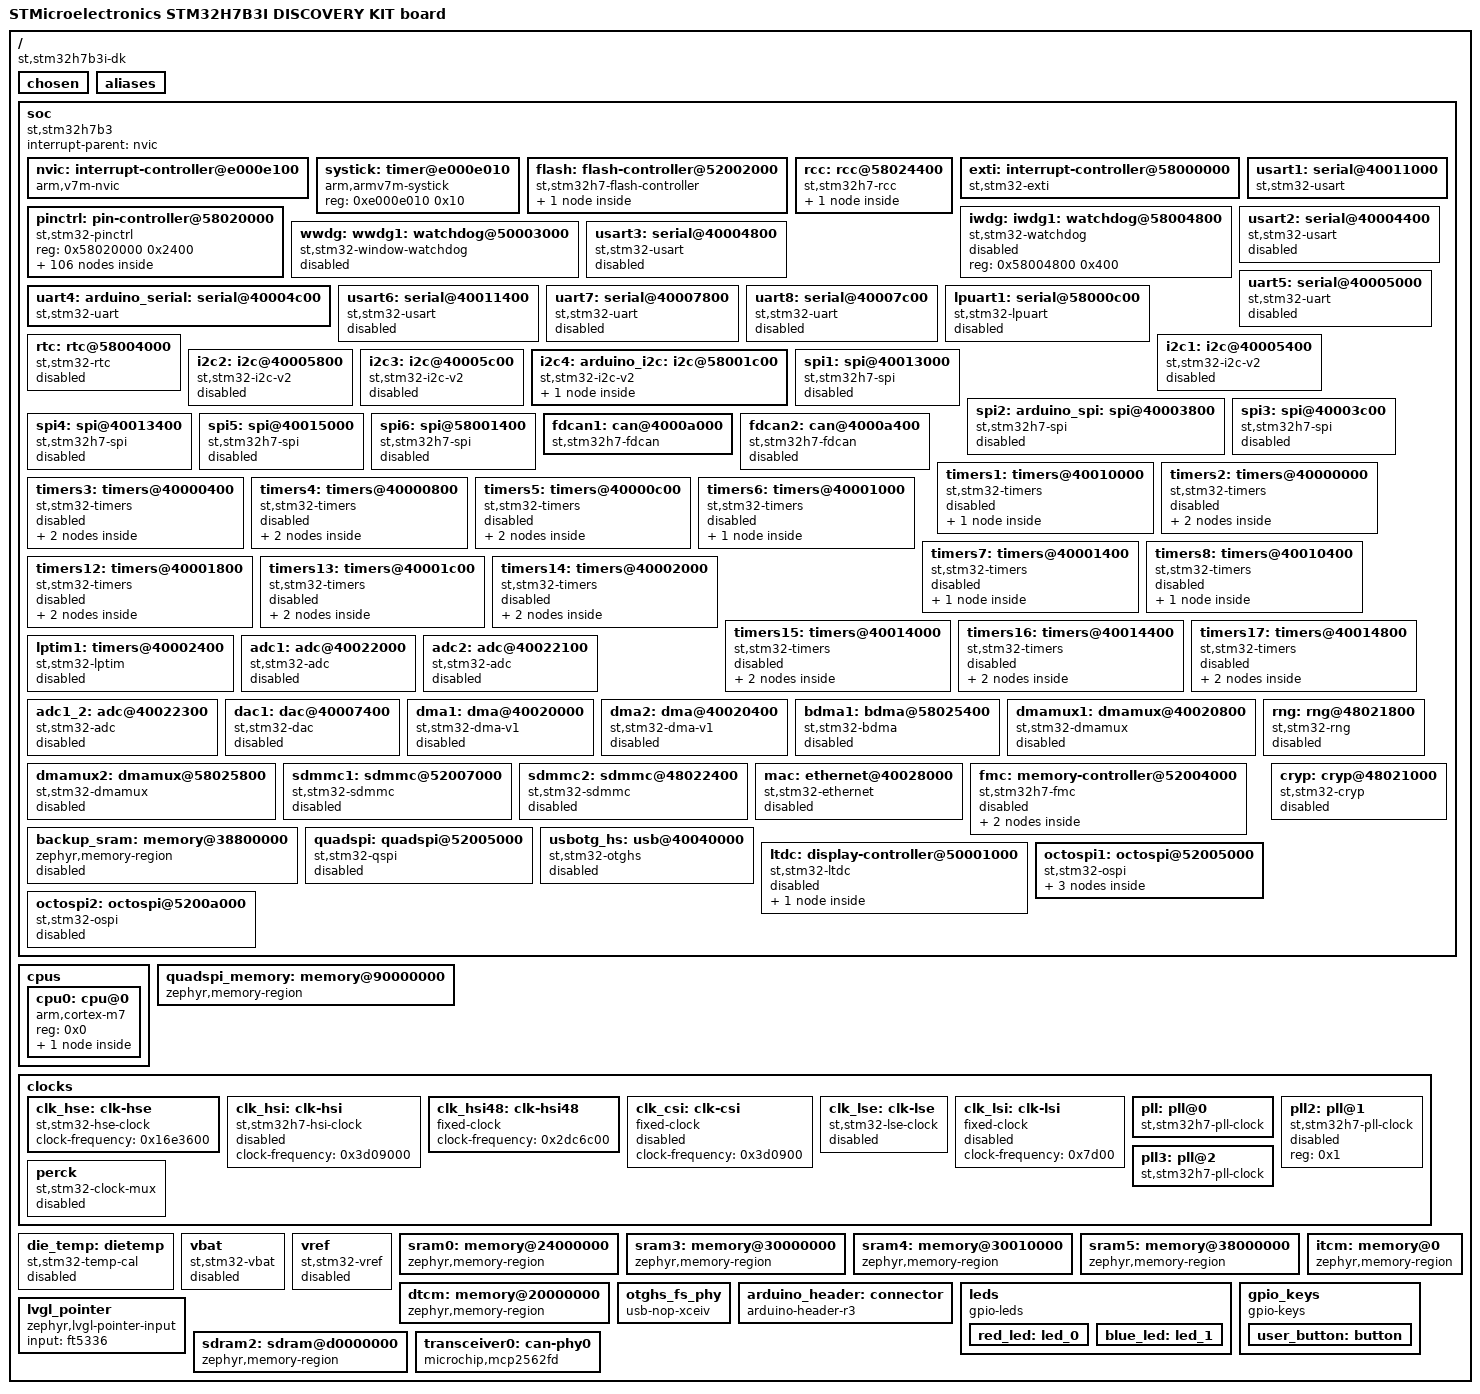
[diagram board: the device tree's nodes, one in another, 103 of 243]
/dts-v1/;

/ {
	#address-cells = < 0x1 >;
	#size-cells = < 0x1 >;
	model = "STMicroelectronics STM32H7B3I DISCOVERY KIT board";
	compatible = "st,stm32h7b3i-dk";
	chosen {
		zephyr,entropy = &rng;
		zephyr,flash-controller = &flash;
		zephyr,console = &usart1;
		zephyr,shell-uart = &usart1;
		zephyr,sram = &sram0;
		zephyr,flash = &flash0;
		zephyr,display = &ltdc;
		zephyr,canbus = &fdcan1;
	};
	aliases {
		led0 = &blue_led;
		led1 = &red_led;
		sw0 = &user_button;
		spi-flash0 = &mx25lm51245;
	};
	soc {
		#address-cells = < 0x1 >;
		#size-cells = < 0x1 >;
		compatible = "st,stm32h7b3", "st,stm32h7", "simple-bus";
		interrupt-parent = < &nvic >;
		ranges;
		nvic: interrupt-controller@e000e100 {
			#address-cells = < 0x1 >;
			compatible = "arm,v7m-nvic";
			reg = < 0xe000e100 0xc00 >;
			interrupt-controller;
			#interrupt-cells = < 0x2 >;
			arm,num-irq-priority-bits = < 0x4 >;
			phandle = < 0x1 >;
		};
		systick: timer@e000e010 {
			compatible = "arm,armv7m-systick";
			reg = < 0xe000e010 0x10 >;
		};
		flash: flash-controller@52002000 {
			compatible = "st,stm32h7-flash-controller";
			reg = < 0x52002000 0x400 >;
			interrupts = < 0x4 0x0 >;
			clocks = < &rcc 0xd4 0x100 >;
			#address-cells = < 0x1 >;
			#size-cells = < 0x1 >;
			flash0: flash@8000000 {
				compatible = "st,stm32-nv-flash", "soc-nv-flash";
				write-block-size = < 0x10 >;
				erase-block-size = < 0x2000 >;
				max-erase-time = < 0x3 >;
				reg = < 0x8000000 0x200000 >;
			};
		};
		rcc: rcc@58024400 {
			compatible = "st,stm32h7-rcc";
			#clock-cells = < 0x2 >;
			reg = < 0x58024400 0x400 >;
			clocks = < &pll >;
			clock-frequency = < 0x10b07600 >;
			d1cpre = < 0x1 >;
			hpre = < 0x1 >;
			d1ppre = < 0x2 >;
			d2ppre1 = < 0x2 >;
			d2ppre2 = < 0x2 >;
			d3ppre = < 0x2 >;
			phandle = < 0x2 >;
			rctl: reset-controller {
				compatible = "st,stm32-rcc-rctl";
				#reset-cells = < 0x1 >;
				phandle = < 0x4 >;
			};
		};
		exti: interrupt-controller@58000000 {
			compatible = "st,stm32-exti";
			interrupt-controller;
			#interrupt-cells = < 0x1 >;
			#address-cells = < 0x1 >;
			reg = < 0x58000000 0x400 >;
			num-lines = < 0x10 >;
			interrupts = < 0x6 0x0 >, < 0x7 0x0 >, < 0x8 0x0 >, < 0x9 0x0 >, < 0xa 0x0 >, < 0x17 0x0 >, < 0x28 0x0 >;
			interrupt-names = "line0", "line1", "line2", "line3", "line4", "line5-9", "line10-15";
			line-ranges = < 0x0 0x1 >, < 0x1 0x1 >, < 0x2 0x1 >, < 0x3 0x1 >, < 0x4 0x1 >, < 0x5 0x5 >, < 0xa 0x6 >;
		};
		pinctrl: pin-controller@58020000 {
			compatible = "st,stm32-pinctrl";
			#address-cells = < 0x1 >;
			#size-cells = < 0x1 >;
			reg = < 0x58020000 0x2400 >;
			gpioa: gpio@58020000 {
				compatible = "st,stm32-gpio";
				gpio-controller;
				#gpio-cells = < 0x2 >;
				reg = < 0x58020000 0x400 >;
				clocks = < &rcc 0xe0 0x1 >;
				phandle = < 0x5d >;
			};
			gpiob: gpio@58020400 {
				compatible = "st,stm32-gpio";
				gpio-controller;
				#gpio-cells = < 0x2 >;
				reg = < 0x58020400 0x400 >;
				clocks = < &rcc 0xe0 0x2 >;
				phandle = < 0x6f >;
			};
			gpioc: gpio@58020800 {
				compatible = "st,stm32-gpio";
				gpio-controller;
				#gpio-cells = < 0x2 >;
				reg = < 0x58020800 0x400 >;
				clocks = < &rcc 0xe0 0x4 >;
				phandle = < 0x6c >;
			};
			gpiod: gpio@58020C00 {
				compatible = "st,stm32-gpio";
				gpio-controller;
				#gpio-cells = < 0x2 >;
				reg = < 0x58020c00 0x400 >;
				clocks = < &rcc 0xe0 0x8 >;
				phandle = < 0x70 >;
			};
			gpioe: gpio@58021000 {
				compatible = "st,stm32-gpio";
				gpio-controller;
				#gpio-cells = < 0x2 >;
				reg = < 0x58021000 0x400 >;
				clocks = < &rcc 0xe0 0x10 >;
				phandle = < 0x6d >;
			};
			gpiof: gpio@58021400 {
				compatible = "st,stm32-gpio";
				gpio-controller;
				#gpio-cells = < 0x2 >;
				reg = < 0x58021400 0x400 >;
				clocks = < &rcc 0xe0 0x20 >;
				phandle = < 0x6e >;
			};
			gpiog: gpio@58021800 {
				compatible = "st,stm32-gpio";
				gpio-controller;
				#gpio-cells = < 0x2 >;
				reg = < 0x58021800 0x400 >;
				clocks = < &rcc 0xe0 0x40 >;
				phandle = < 0x71 >;
			};
			gpioh: gpio@58021C00 {
				compatible = "st,stm32-gpio";
				gpio-controller;
				#gpio-cells = < 0x2 >;
				reg = < 0x58021c00 0x400 >;
				clocks = < &rcc 0xe0 0x80 >;
				phandle = < 0xb >;
			};
			gpioi: gpio@58022000 {
				compatible = "st,stm32-gpio";
				gpio-controller;
				#gpio-cells = < 0x2 >;
				reg = < 0x58022000 0x400 >;
				clocks = < &rcc 0xe0 0x100 >;
				phandle = < 0x19 >;
			};
			gpioj: gpio@58022400 {
				compatible = "st,stm32-gpio";
				gpio-controller;
				#gpio-cells = < 0x2 >;
				reg = < 0x58022400 0x400 >;
				clocks = < &rcc 0xe0 0x200 >;
			};
			gpiok: gpio@58022800 {
				compatible = "st,stm32-gpio";
				gpio-controller;
				#gpio-cells = < 0x2 >;
				reg = < 0x58022800 0x400 >;
				clocks = < &rcc 0xe0 0x400 >;
			};
			fdcan1_rx_pa11: fdcan1_rx_pa11 {
				pinmux = < 0x169 >;
				phandle = < 0x10 >;
			};
			fdcan1_tx_pa12: fdcan1_tx_pa12 {
				pinmux = < 0x189 >;
				phandle = < 0x11 >;
			};
			fmc_d2_pd0: fmc_d2_pd0 {
				pinmux = < 0x60c >;
				bias-pull-up;
				slew-rate = "very-high-speed";
				phandle = < 0x32 >;
			};
			fmc_d3_pd1: fmc_d3_pd1 {
				pinmux = < 0x62c >;
				bias-pull-up;
				slew-rate = "very-high-speed";
				phandle = < 0x33 >;
			};
			fmc_d13_pd8: fmc_d13_pd8 {
				pinmux = < 0x70c >;
				bias-pull-up;
				slew-rate = "very-high-speed";
				phandle = < 0x3d >;
			};
			fmc_d14_pd9: fmc_d14_pd9 {
				pinmux = < 0x72c >;
				bias-pull-up;
				slew-rate = "very-high-speed";
				phandle = < 0x3e >;
			};
			fmc_d15_pd10: fmc_d15_pd10 {
				pinmux = < 0x74c >;
				bias-pull-up;
				slew-rate = "very-high-speed";
				phandle = < 0x3f >;
			};
			fmc_d0_pd14: fmc_d0_pd14 {
				pinmux = < 0x7cc >;
				bias-pull-up;
				slew-rate = "very-high-speed";
				phandle = < 0x30 >;
			};
			fmc_d1_pd15: fmc_d1_pd15 {
				pinmux = < 0x7ec >;
				bias-pull-up;
				slew-rate = "very-high-speed";
				phandle = < 0x31 >;
			};
			fmc_nbl0_pe0: fmc_nbl0_pe0 {
				pinmux = < 0x80c >;
				bias-pull-up;
				slew-rate = "very-high-speed";
				phandle = < 0x1a >;
			};
			fmc_nbl1_pe1: fmc_nbl1_pe1 {
				pinmux = < 0x82c >;
				bias-pull-up;
				slew-rate = "very-high-speed";
				phandle = < 0x1b >;
			};
			fmc_d4_pe7: fmc_d4_pe7 {
				pinmux = < 0x8ec >;
				bias-pull-up;
				slew-rate = "very-high-speed";
				phandle = < 0x34 >;
			};
			fmc_d5_pe8: fmc_d5_pe8 {
				pinmux = < 0x90c >;
				bias-pull-up;
				slew-rate = "very-high-speed";
				phandle = < 0x35 >;
			};
			fmc_d6_pe9: fmc_d6_pe9 {
				pinmux = < 0x92c >;
				bias-pull-up;
				slew-rate = "very-high-speed";
				phandle = < 0x36 >;
			};
			fmc_d7_pe10: fmc_d7_pe10 {
				pinmux = < 0x94c >;
				bias-pull-up;
				slew-rate = "very-high-speed";
				phandle = < 0x37 >;
			};
			fmc_d8_pe11: fmc_d8_pe11 {
				pinmux = < 0x96c >;
				bias-pull-up;
				slew-rate = "very-high-speed";
				phandle = < 0x38 >;
			};
			fmc_d9_pe12: fmc_d9_pe12 {
				pinmux = < 0x98c >;
				bias-pull-up;
				slew-rate = "very-high-speed";
				phandle = < 0x39 >;
			};
			fmc_d10_pe13: fmc_d10_pe13 {
				pinmux = < 0x9ac >;
				bias-pull-up;
				slew-rate = "very-high-speed";
				phandle = < 0x3a >;
			};
			fmc_d11_pe14: fmc_d11_pe14 {
				pinmux = < 0x9cc >;
				bias-pull-up;
				slew-rate = "very-high-speed";
				phandle = < 0x3b >;
			};
			fmc_d12_pe15: fmc_d12_pe15 {
				pinmux = < 0x9ec >;
				bias-pull-up;
				slew-rate = "very-high-speed";
				phandle = < 0x3c >;
			};
			fmc_a0_pf0: fmc_a0_pf0 {
				pinmux = < 0xa0c >;
				bias-pull-up;
				slew-rate = "very-high-speed";
				phandle = < 0x22 >;
			};
			fmc_a1_pf1: fmc_a1_pf1 {
				pinmux = < 0xa2c >;
				bias-pull-up;
				slew-rate = "very-high-speed";
				phandle = < 0x23 >;
			};
			fmc_a2_pf2: fmc_a2_pf2 {
				pinmux = < 0xa4c >;
				bias-pull-up;
				slew-rate = "very-high-speed";
				phandle = < 0x24 >;
			};
			fmc_a3_pf3: fmc_a3_pf3 {
				pinmux = < 0xa6c >;
				bias-pull-up;
				slew-rate = "very-high-speed";
				phandle = < 0x25 >;
			};
			fmc_a4_pf4: fmc_a4_pf4 {
				pinmux = < 0xa8c >;
				bias-pull-up;
				slew-rate = "very-high-speed";
				phandle = < 0x26 >;
			};
			fmc_a5_pf5: fmc_a5_pf5 {
				pinmux = < 0xaac >;
				bias-pull-up;
				slew-rate = "very-high-speed";
				phandle = < 0x27 >;
			};
			fmc_sdnras_pf11: fmc_sdnras_pf11 {
				pinmux = < 0xb6c >;
				bias-pull-up;
				slew-rate = "very-high-speed";
				phandle = < 0x20 >;
			};
			fmc_a6_pf12: fmc_a6_pf12 {
				pinmux = < 0xb8c >;
				bias-pull-up;
				slew-rate = "very-high-speed";
				phandle = < 0x28 >;
			};
			fmc_a7_pf13: fmc_a7_pf13 {
				pinmux = < 0xbac >;
				bias-pull-up;
				slew-rate = "very-high-speed";
				phandle = < 0x29 >;
			};
			fmc_a8_pf14: fmc_a8_pf14 {
				pinmux = < 0xbcc >;
				bias-pull-up;
				slew-rate = "very-high-speed";
				phandle = < 0x2a >;
			};
			fmc_a9_pf15: fmc_a9_pf15 {
				pinmux = < 0xbec >;
				bias-pull-up;
				slew-rate = "very-high-speed";
				phandle = < 0x2b >;
			};
			fmc_a10_pg0: fmc_a10_pg0 {
				pinmux = < 0xc0c >;
				bias-pull-up;
				slew-rate = "very-high-speed";
				phandle = < 0x2c >;
			};
			fmc_a11_pg1: fmc_a11_pg1 {
				pinmux = < 0xc2c >;
				bias-pull-up;
				slew-rate = "very-high-speed";
				phandle = < 0x2d >;
			};
			fmc_a14_pg4: fmc_a14_pg4 {
				pinmux = < 0xc8c >;
				bias-pull-up;
				slew-rate = "very-high-speed";
				phandle = < 0x2e >;
			};
			fmc_a15_pg5: fmc_a15_pg5 {
				pinmux = < 0xcac >;
				bias-pull-up;
				slew-rate = "very-high-speed";
				phandle = < 0x2f >;
			};
			fmc_sdclk_pg8: fmc_sdclk_pg8 {
				pinmux = < 0xd0c >;
				bias-pull-up;
				slew-rate = "very-high-speed";
				phandle = < 0x1c >;
			};
			fmc_sdncas_pg15: fmc_sdncas_pg15 {
				pinmux = < 0xdec >;
				bias-pull-up;
				slew-rate = "very-high-speed";
				phandle = < 0x21 >;
			};
			fmc_sdnwe_ph5: fmc_sdnwe_ph5 {
				pinmux = < 0xeac >;
				bias-pull-up;
				slew-rate = "very-high-speed";
				phandle = < 0x1d >;
			};
			fmc_sdne1_ph6: fmc_sdne1_ph6 {
				pinmux = < 0xecc >;
				bias-pull-up;
				slew-rate = "very-high-speed";
				phandle = < 0x1f >;
			};
			fmc_sdcke1_ph7: fmc_sdcke1_ph7 {
				pinmux = < 0xeec >;
				bias-pull-up;
				slew-rate = "very-high-speed";
				phandle = < 0x1e >;
			};
			i2c4_scl_pd12: i2c4_scl_pd12 {
				pinmux = < 0x784 >;
				bias-pull-up;
				drive-open-drain;
				phandle = < 0x9 >;
			};
			i2c4_sda_pd13: i2c4_sda_pd13 {
				pinmux = < 0x7a4 >;
				bias-pull-up;
				drive-open-drain;
				phandle = < 0xa >;
			};
			ltdc_hsync_pi12: ltdc_hsync_pi12 {
				pinmux = < 0x118e >;
				phandle = < 0x5b >;
			};
			ltdc_vsync_pi13: ltdc_vsync_pi13 {
				pinmux = < 0x11ae >;
				phandle = < 0x5c >;
			};
			ltdc_clk_pi14: ltdc_clk_pi14 {
				pinmux = < 0x11ce >;
				phandle = < 0x5a >;
			};
			ltdc_r0_pi15: ltdc_r0_pi15 {
				pinmux = < 0x11ee >;
				phandle = < 0x41 >;
			};
			ltdc_r1_pj0: ltdc_r1_pj0 {
				pinmux = < 0x120e >;
				phandle = < 0x42 >;
			};
			ltdc_r2_pj1: ltdc_r2_pj1 {
				pinmux = < 0x122e >;
				phandle = < 0x43 >;
			};
			ltdc_r3_pj2: ltdc_r3_pj2 {
				pinmux = < 0x124e >;
				phandle = < 0x44 >;
			};
			ltdc_r4_pj3: ltdc_r4_pj3 {
				pinmux = < 0x126e >;
				phandle = < 0x45 >;
			};
			ltdc_r5_pj4: ltdc_r5_pj4 {
				pinmux = < 0x128e >;
				phandle = < 0x46 >;
			};
			ltdc_r6_pj5: ltdc_r6_pj5 {
				pinmux = < 0x12ae >;
				phandle = < 0x47 >;
			};
			ltdc_r7_pj6: ltdc_r7_pj6 {
				pinmux = < 0x12ce >;
				phandle = < 0x48 >;
			};
			ltdc_g0_pj7: ltdc_g0_pj7 {
				pinmux = < 0x12ee >;
				phandle = < 0x49 >;
			};
			ltdc_g1_pj8: ltdc_g1_pj8 {
				pinmux = < 0x130e >;
				phandle = < 0x4a >;
			};
			ltdc_g2_pj9: ltdc_g2_pj9 {
				pinmux = < 0x132e >;
				phandle = < 0x4b >;
			};
			ltdc_g3_pj10: ltdc_g3_pj10 {
				pinmux = < 0x134e >;
				phandle = < 0x4c >;
			};
			ltdc_g4_pj11: ltdc_g4_pj11 {
				pinmux = < 0x136e >;
				phandle = < 0x4d >;
			};
			ltdc_b0_pj12: ltdc_b0_pj12 {
				pinmux = < 0x138e >;
				phandle = < 0x51 >;
			};
			ltdc_b1_pj13: ltdc_b1_pj13 {
				pinmux = < 0x13ae >;
				phandle = < 0x52 >;
			};
			ltdc_b2_pj14: ltdc_b2_pj14 {
				pinmux = < 0x13ce >;
				phandle = < 0x53 >;
			};
			ltdc_b3_pj15: ltdc_b3_pj15 {
				pinmux = < 0x13ee >;
				phandle = < 0x54 >;
			};
			ltdc_g5_pk0: ltdc_g5_pk0 {
				pinmux = < 0x140e >;
				phandle = < 0x4e >;
			};
			ltdc_g6_pk1: ltdc_g6_pk1 {
				pinmux = < 0x142e >;
				phandle = < 0x4f >;
			};
			ltdc_g7_pk2: ltdc_g7_pk2 {
				pinmux = < 0x144e >;
				phandle = < 0x50 >;
			};
			ltdc_b4_pk3: ltdc_b4_pk3 {
				pinmux = < 0x146e >;
				phandle = < 0x55 >;
			};
			ltdc_b5_pk4: ltdc_b5_pk4 {
				pinmux = < 0x148e >;
				phandle = < 0x56 >;
			};
			ltdc_b6_pk5: ltdc_b6_pk5 {
				pinmux = < 0x14ae >;
				phandle = < 0x57 >;
			};
			ltdc_b7_pk6: ltdc_b7_pk6 {
				pinmux = < 0x14ce >;
				phandle = < 0x58 >;
			};
			ltdc_de_pk7: ltdc_de_pk7 {
				pinmux = < 0x14ee >;
				phandle = < 0x59 >;
			};
			octospim_p1_io3_pa1_c: octospim_p1_io3_pa1_c {
				pinmux = < 0x29 >;
				slew-rate = "very-high-speed";
				phandle = < 0x64 >;
			};
			octospim_p1_ncs_pb6: octospim_p1_ncs_pb6 {
				pinmux = < 0x2ca >;
				slew-rate = "very-high-speed";
				phandle = < 0x60 >;
			};
			octospim_p1_io4_pc1: octospim_p1_io4_pc1 {
				pinmux = < 0x42a >;
				slew-rate = "very-high-speed";
				phandle = < 0x65 >;
			};
			octospim_p1_dqs_pc5: octospim_p1_dqs_pc5 {
				pinmux = < 0x4aa >;
				slew-rate = "very-high-speed";
				phandle = < 0x69 >;
			};
			octospim_p1_io7_pd7: octospim_p1_io7_pd7 {
				pinmux = < 0x6ea >;
				slew-rate = "very-high-speed";
				phandle = < 0x68 >;
			};
			octospim_p1_io2_pe2: octospim_p1_io2_pe2 {
				pinmux = < 0x849 >;
				slew-rate = "very-high-speed";
				phandle = < 0x63 >;
			};
			octospim_p1_clk_pf10: octospim_p1_clk_pf10 {
				pinmux = < 0xb49 >;
				slew-rate = "very-high-speed";
				phandle = < 0x5f >;
			};
			octospim_p1_io6_pg9: octospim_p1_io6_pg9 {
				pinmux = < 0xd29 >;
				slew-rate = "very-high-speed";
				phandle = < 0x67 >;
			};
			octospim_p1_io5_ph3: octospim_p1_io5_ph3 {
				pinmux = < 0xe69 >;
				slew-rate = "very-high-speed";
				phandle = < 0x66 >;
			};
			octospim_p2_io0_pi9: octospim_p2_io0_pi9 {
				pinmux = < 0x1123 >;
				slew-rate = "very-high-speed";
				phandle = < 0x61 >;
			};
			octospim_p2_io1_pi10: octospim_p2_io1_pi10 {
				pinmux = < 0x1143 >;
				slew-rate = "very-high-speed";
				phandle = < 0x62 >;
			};
			sdmmc1_d0_pc8: sdmmc1_d0_pc8 {
				pinmux = < 0x50c >;
				bias-pull-up;
				slew-rate = "very-high-speed";
				phandle = < 0x13 >;
			};
			sdmmc1_d1_pc9: sdmmc1_d1_pc9 {
				pinmux = < 0x52c >;
				bias-pull-up;
				slew-rate = "very-high-speed";
				phandle = < 0x14 >;
			};
			sdmmc1_d2_pc10: sdmmc1_d2_pc10 {
				pinmux = < 0x54c >;
				bias-pull-up;
				slew-rate = "very-high-speed";
				phandle = < 0x15 >;
			};
			sdmmc1_d3_pc11: sdmmc1_d3_pc11 {
				pinmux = < 0x56c >;
				bias-pull-up;
				slew-rate = "very-high-speed";
				phandle = < 0x16 >;
			};
			sdmmc1_ck_pc12: sdmmc1_ck_pc12 {
				pinmux = < 0x58c >;
				bias-pull-up;
				slew-rate = "very-high-speed";
				phandle = < 0x17 >;
			};
			sdmmc1_cmd_pd2: sdmmc1_cmd_pd2 {
				pinmux = < 0x64c >;
				bias-pull-up;
				slew-rate = "very-high-speed";
				phandle = < 0x18 >;
			};
			spi2_miso_pb14: spi2_miso_pb14 {
				pinmux = < 0x3c5 >;
				bias-pull-down;
				phandle = < 0xd >;
			};
			spi2_mosi_pb15: spi2_mosi_pb15 {
				pinmux = < 0x3e5 >;
				bias-pull-down;
				phandle = < 0xe >;
			};
			spi2_nss_pi0: spi2_nss_pi0 {
				pinmux = < 0x1005 >;
				bias-pull-up;
				phandle = < 0xf >;
			};
			spi2_sck_pa12: spi2_sck_pa12 {
				pinmux = < 0x185 >;
				bias-pull-down;
				slew-rate = "very-high-speed";
				phandle = < 0xc >;
			};
			usart1_rx_pa10: usart1_rx_pa10 {
				pinmux = < 0x147 >;
				phandle = < 0x6 >;
			};
			uart4_rx_ph14: uart4_rx_ph14 {
				pinmux = < 0xfc8 >;
				phandle = < 0x8 >;
			};
			usart1_tx_pa9: usart1_tx_pa9 {
				pinmux = < 0x127 >;
				bias-pull-up;
				phandle = < 0x5 >;
			};
			uart4_tx_ph13: uart4_tx_ph13 {
				pinmux = < 0xfa8 >;
				bias-pull-up;
				phandle = < 0x7 >;
			};
		};
		iwdg: iwdg1: watchdog@58004800 {
			compatible = "st,stm32-watchdog";
			reg = < 0x58004800 0x400 >;
			status = "disabled";
		};
		wwdg: wwdg1: watchdog@50003000 {
			compatible = "st,stm32-window-watchdog";
			reg = < 0x50003000 0x1000 >;
			clocks = < &rcc 0xe4 0x40 >;
			interrupts = < 0x0 0x7 >;
			status = "disabled";
		};
		usart1: serial@40011000 {
			compatible = "st,stm32-usart", "st,stm32-uart";
			reg = < 0x40011000 0x400 >;
			clocks = < &rcc 0xf0 0x10 >;
			resets = < &rctl 0x1304 >;
			interrupts = < 0x25 0x0 >;
			status = "okay";
			pinctrl-0 = < &usart1_tx_pa9 &usart1_rx_pa10 >;
			pinctrl-names = "default";
			current-speed = < 0x1c200 >;
		};
		usart2: serial@40004400 {
			compatible = "st,stm32-usart", "st,stm32-uart";
			reg = < 0x40004400 0x400 >;
			clocks = < &rcc 0xe8 0x20000 >;
			resets = < &rctl 0x1211 >;
			interrupts = < 0x26 0x0 >;
			status = "disabled";
		};
		usart3: serial@40004800 {
			compatible = "st,stm32-usart", "st,stm32-uart";
			reg = < 0x40004800 0x400 >;
			clocks = < &rcc 0xe8 0x40000 >;
			resets = < &rctl 0x1212 >;
			interrupts = < 0x27 0x0 >;
			status = "disabled";
		};
		uart4: arduino_serial: serial@40004c00 {
			compatible = "st,stm32-uart";
			reg = < 0x40004c00 0x400 >;
			clocks = < &rcc 0xe8 0x80000 >;
			resets = < &rctl 0x1213 >;
			interrupts = < 0x34 0x0 >;
			status = "okay";
			pinctrl-0 = < &uart4_tx_ph13 &uart4_rx_ph14 >;
			pinctrl-names = "default";
			current-speed = < 0x1c200 >;
		};
		uart5: serial@40005000 {
			compatible = "st,stm32-uart";
			reg = < 0x40005000 0x400 >;
			clocks = < &rcc 0xe8 0x100000 >;
			resets = < &rctl 0x1214 >;
			interrupts = < 0x35 0x0 >;
			status = "disabled";
		};
		usart6: serial@40011400 {
			compatible = "st,stm32-usart", "st,stm32-uart";
			reg = < 0x40011400 0x400 >;
			clocks = < &rcc 0xf0 0x20 >;
			resets = < &rctl 0x1305 >;
			interrupts = < 0x47 0x0 >;
			status = "disabled";
		};
		uart7: serial@40007800 {
			compatible = "st,stm32-uart";
			reg = < 0x40007800 0x400 >;
			clocks = < &rcc 0xe8 0x40000000 >;
			resets = < &rctl 0x121e >;
			interrupts = < 0x52 0x0 >;
			status = "disabled";
		};
		uart8: serial@40007c00 {
			compatible = "st,stm32-uart";
			reg = < 0x40007c00 0x400 >;
			clocks = < &rcc 0xe8 0x80000000 >;
			resets = < &rctl 0x121f >;
			interrupts = < 0x53 0x0 >;
			status = "disabled";
		};
		lpuart1: serial@58000c00 {
			compatible = "st,stm32-lpuart", "st,stm32-uart";
			reg = < 0x58000c00 0x400 >;
			clocks = < &rcc 0xf4 0x8 >;
			resets = < &rctl 0x1383 >;
			interrupts = < 0x8e 0x0 >;
			status = "disabled";
		};
		rtc: rtc@58004000 {
			compatible = "st,stm32-rtc";
			reg = < 0x58004000 0x400 >;
			interrupts = < 0x29 0x0 >;
			clocks = < &rcc 0xf4 0x10000 >;
			prescaler = < 0x8000 >;
			status = "disabled";
		};
		i2c1: i2c@40005400 {
			compatible = "st,stm32-i2c-v2";
			clock-frequency = < 0x186a0 >;
			#address-cells = < 0x1 >;
			#size-cells = < 0x0 >;
			reg = < 0x40005400 0x400 >;
			clocks = < &rcc 0xe8 0x200000 >;
			interrupts = < 0x1f 0x0 >, < 0x20 0x0 >;
			interrupt-names = "event", "error";
			status = "disabled";
		};
		i2c2: i2c@40005800 {
			compatible = "st,stm32-i2c-v2";
			clock-frequency = < 0x186a0 >;
			#address-cells = < 0x1 >;
			#size-cells = < 0x0 >;
			reg = < 0x40005800 0x400 >;
			clocks = < &rcc 0xe8 0x400000 >;
			interrupts = < 0x21 0x0 >, < 0x22 0x0 >;
			interrupt-names = "event", "error";
			status = "disabled";
		};
		i2c3: i2c@40005c00 {
			compatible = "st,stm32-i2c-v2";
			clock-frequency = < 0x186a0 >;
			#address-cells = < 0x1 >;
			#size-cells = < 0x0 >;
			reg = < 0x40005c00 0x400 >;
			clocks = < &rcc 0xe8 0x800000 >;
			interrupts = < 0x48 0x0 >, < 0x49 0x0 >;
			interrupt-names = "event", "error";
			status = "disabled";
		};
		i2c4: arduino_i2c: i2c@58001c00 {
			compatible = "st,stm32-i2c-v2";
			clock-frequency = < 0x61a80 >;
			#address-cells = < 0x1 >;
			#size-cells = < 0x0 >;
			reg = < 0x58001c00 0x400 >;
			clocks = < &rcc 0xf4 0x80 >;
			interrupts = < 0x5f 0x0 >, < 0x60 0x0 >;
			interrupt-names = "event", "error";
			status = "okay";
			pinctrl-0 = < &i2c4_scl_pd12 &i2c4_sda_pd13 >;
			pinctrl-names = "default";
			ft5336: ft5336@38 {
				compatible = "focaltech,ft5336";
				reg = < 0x38 >;
				int-gpios = < &gpioh 0x2 0x0 >;
				phandle = < 0x72 >;
			};
		};
		spi1: spi@40013000 {
			compatible = "st,stm32h7-spi", "st,stm32-spi-fifo", "st,stm32-spi";
			#address-cells = < 0x1 >;
			#size-cells = < 0x0 >;
			reg = < 0x40013000 0x400 >;
			clocks = < &rcc 0xf0 0x1000 >, < &rcc 0x2 0xec50 >;
			interrupts = < 0x23 0x0 >;
			status = "disabled";
		};
		spi2: arduino_spi: spi@40003800 {
			compatible = "st,stm32h7-spi", "st,stm32-spi-fifo", "st,stm32-spi";
			#address-cells = < 0x1 >;
			#size-cells = < 0x0 >;
			reg = < 0x40003800 0x400 >;
			clocks = < &rcc 0xe8 0x4000 >, < &rcc 0x2 0xec50 >;
			interrupts = < 0x24 0x0 >;
			status = "disabled";
			pinctrl-0 = < &spi2_sck_pa12 &spi2_miso_pb14 &spi2_mosi_pb15 &spi2_nss_pi0 >;
			pinctrl-names = "default";
		};
		spi3: spi@40003c00 {
			compatible = "st,stm32h7-spi", "st,stm32-spi-fifo", "st,stm32-spi";
			#address-cells = < 0x1 >;
			#size-cells = < 0x0 >;
			reg = < 0x40003c00 0x400 >;
			clocks = < &rcc 0xe8 0x8000 >, < &rcc 0x2 0xec50 >;
			interrupts = < 0x33 0x0 >;
			status = "disabled";
		};
		spi4: spi@40013400 {
			compatible = "st,stm32h7-spi", "st,stm32-spi-fifo", "st,stm32-spi";
			#address-cells = < 0x1 >;
			#size-cells = < 0x0 >;
			reg = < 0x40013400 0x400 >;
			clocks = < &rcc 0xf0 0x2000 >;
			interrupts = < 0x54 0x0 >;
			status = "disabled";
		};
		spi5: spi@40015000 {
			compatible = "st,stm32h7-spi", "st,stm32-spi-fifo", "st,stm32-spi";
			#address-cells = < 0x1 >;
			#size-cells = < 0x0 >;
			reg = < 0x40015000 0x400 >;
			clocks = < &rcc 0xf0 0x100000 >;
			interrupts = < 0x55 0x0 >;
			status = "disabled";
		};
		spi6: spi@58001400 {
			compatible = "st,stm32h7-spi", "st,stm32-spi-fifo", "st,stm32-spi";
			#address-cells = < 0x1 >;
			#size-cells = < 0x0 >;
			reg = < 0x58001400 0x400 >;
			clocks = < &rcc 0xf4 0x20 >;
			interrupts = < 0x56 0x0 >;
			status = "disabled";
		};
		fdcan1: can@4000a000 {
			compatible = "st,stm32h7-fdcan";
			reg = < 0x4000a000 0x400 >, < 0x4000ac00 0x350 >;
			reg-names = "m_can", "message_ram";
			clocks = < &rcc 0xec 0x100 >;
			interrupts = < 0x13 0x0 >, < 0x15 0x0 >, < 0x3f 0x0 >;
			interrupt-names = "LINE_0", "LINE_1", "CALIB";
			bosch,mram-cfg = < 0x0 0x1c 0x8 0x3 0x3 0x0 0x3 0x3 >;
			sjw = < 0x1 >;
			sample-point = < 0x36b >;
			sjw-data = < 0x1 >;
			sample-point-data = < 0x36b >;
			status = "okay";
			pinctrl-0 = < &fdcan1_rx_pa11 &fdcan1_tx_pa12 >;
			pinctrl-names = "default";
			phys = < &transceiver0 >;
			bus-speed = < 0x1e848 >;
			bus-speed-data = < 0xf4240 >;
		};
		fdcan2: can@4000a400 {
			compatible = "st,stm32h7-fdcan";
			reg = < 0x4000a400 0x400 >, < 0x4000ac00 0x6a0 >;
			reg-names = "m_can", "message_ram";
			clocks = < &rcc 0xec 0x100 >;
			interrupts = < 0x14 0x0 >, < 0x16 0x0 >, < 0x3f 0x0 >;
			interrupt-names = "LINE_0", "LINE_1", "CALIB";
			bosch,mram-cfg = < 0x350 0x1c 0x8 0x3 0x3 0x0 0x3 0x3 >;
			sjw = < 0x1 >;
			sample-point = < 0x36b >;
			sjw-data = < 0x1 >;
			sample-point-data = < 0x36b >;
			status = "disabled";
		};
		timers1: timers@40010000 {
			compatible = "st,stm32-timers";
			reg = < 0x40010000 0x400 >;
			clocks = < &rcc 0xf0 0x1 >;
			resets = < &rctl 0x1300 >;
			interrupts = < 0x18 0x0 >, < 0x19 0x0 >, < 0x1a 0x0 >, < 0x1b 0x0 >;
			interrupt-names = "brk", "up", "trgcom", "cc";
			st,prescaler = < 0x0 >;
			status = "disabled";
			pwm {
				compatible = "st,stm32-pwm";
				status = "disabled";
				#pwm-cells = < 0x3 >;
			};
		};
		timers2: timers@40000000 {
			compatible = "st,stm32-timers";
			reg = < 0x40000000 0x400 >;
			clocks = < &rcc 0xe8 0x1 >;
			resets = < &rctl 0x1200 >;
			interrupts = < 0x1c 0x0 >;
			interrupt-names = "global";
			st,prescaler = < 0x0 >;
			status = "disabled";
			pwm {
				compatible = "st,stm32-pwm";
				status = "disabled";
				#pwm-cells = < 0x3 >;
			};
			counter {
				compatible = "st,stm32-counter";
				status = "disabled";
			};
		};
		timers3: timers@40000400 {
			compatible = "st,stm32-timers";
			reg = < 0x40000400 0x400 >;
			clocks = < &rcc 0xe8 0x2 >;
			resets = < &rctl 0x1201 >;
			interrupts = < 0x1d 0x0 >;
			interrupt-names = "global";
			st,prescaler = < 0x0 >;
			status = "disabled";
			pwm {
				compatible = "st,stm32-pwm";
				status = "disabled";
				#pwm-cells = < 0x3 >;
			};
			counter {
				compatible = "st,stm32-counter";
				status = "disabled";
			};
		};
		timers4: timers@40000800 {
			compatible = "st,stm32-timers";
			reg = < 0x40000800 0x400 >;
			clocks = < &rcc 0xe8 0x4 >;
			resets = < &rctl 0x1202 >;
			interrupts = < 0x1e 0x0 >;
			interrupt-names = "global";
			st,prescaler = < 0x0 >;
			status = "disabled";
			pwm {
				compatible = "st,stm32-pwm";
				status = "disabled";
				#pwm-cells = < 0x3 >;
			};
			counter {
				compatible = "st,stm32-counter";
				status = "disabled";
			};
		};
		timers5: timers@40000c00 {
			compatible = "st,stm32-timers";
			reg = < 0x40000c00 0x400 >;
			clocks = < &rcc 0xe8 0x8 >;
			resets = < &rctl 0x1203 >;
			interrupts = < 0x32 0x0 >;
			interrupt-names = "global";
			st,prescaler = < 0x0 >;
			status = "disabled";
			pwm {
				compatible = "st,stm32-pwm";
				status = "disabled";
				#pwm-cells = < 0x3 >;
			};
			counter {
				compatible = "st,stm32-counter";
				status = "disabled";
			};
		};
		timers6: timers@40001000 {
			compatible = "st,stm32-timers";
			reg = < 0x40001000 0x400 >;
			clocks = < &rcc 0xe8 0x10 >;
			resets = < &rctl 0x1204 >;
			interrupts = < 0x36 0x0 >;
			interrupt-names = "global";
			st,prescaler = < 0x0 >;
			status = "disabled";
			counter {
				compatible = "st,stm32-counter";
				status = "disabled";
			};
		};
		timers7: timers@40001400 {
			compatible = "st,stm32-timers";
			reg = < 0x40001400 0x400 >;
			clocks = < &rcc 0xe8 0x20 >;
			resets = < &rctl 0x1205 >;
			interrupts = < 0x37 0x0 >;
			interrupt-names = "global";
			st,prescaler = < 0x0 >;
			status = "disabled";
			counter {
				compatible = "st,stm32-counter";
				status = "disabled";
			};
		};
		timers8: timers@40010400 {
			compatible = "st,stm32-timers";
			reg = < 0x40010400 0x400 >;
			clocks = < &rcc 0xf0 0x2 >;
			resets = < &rctl 0x1301 >;
			interrupts = < 0x2b 0x0 >, < 0x2c 0x0 >, < 0x2d 0x0 >, < 0x2e 0x0 >;
			interrupt-names = "brk", "up", "trgcom", "cc";
			st,prescaler = < 0x0 >;
			status = "disabled";
			pwm {
				compatible = "st,stm32-pwm";
				status = "disabled";
				#pwm-cells = < 0x3 >;
			};
		};
		timers12: timers@40001800 {
			compatible = "st,stm32-timers";
			reg = < 0x40001800 0x400 >;
			clocks = < &rcc 0xe8 0x40 >;
			resets = < &rctl 0x1206 >;
			interrupts = < 0x2b 0x0 >;
			interrupt-names = "global";
			st,prescaler = < 0x0 >;
			status = "disabled";
			pwm {
				compatible = "st,stm32-pwm";
				status = "disabled";
				#pwm-cells = < 0x3 >;
			};
			counter {
				compatible = "st,stm32-counter";
				status = "disabled";
			};
		};
		timers13: timers@40001c00 {
			compatible = "st,stm32-timers";
			reg = < 0x40001c00 0x400 >;
			clocks = < &rcc 0xe8 0x80 >;
			resets = < &rctl 0x1207 >;
			interrupts = < 0x2c 0x0 >;
			interrupt-names = "global";
			st,prescaler = < 0x0 >;
			status = "disabled";
			pwm {
				compatible = "st,stm32-pwm";
				status = "disabled";
				#pwm-cells = < 0x3 >;
			};
			counter {
				compatible = "st,stm32-counter";
				status = "disabled";
			};
		};
		timers14: timers@40002000 {
			compatible = "st,stm32-timers";
			reg = < 0x40002000 0x400 >;
			clocks = < &rcc 0xe8 0x100 >;
			resets = < &rctl 0x1208 >;
			interrupts = < 0x2d 0x0 >;
			interrupt-names = "global";
			st,prescaler = < 0x0 >;
			status = "disabled";
			pwm {
				compatible = "st,stm32-pwm";
				status = "disabled";
				#pwm-cells = < 0x3 >;
			};
			counter {
				compatible = "st,stm32-counter";
				status = "disabled";
			};
		};
		timers15: timers@40014000 {
			compatible = "st,stm32-timers";
			reg = < 0x40014000 0x400 >;
			clocks = < &rcc 0xf0 0x10000 >;
			resets = < &rctl 0x1310 >;
			interrupts = < 0x74 0x0 >;
			interrupt-names = "global";
			st,prescaler = < 0x0 >;
			status = "disabled";
			pwm {
				compatible = "st,stm32-pwm";
				status = "disabled";
				#pwm-cells = < 0x3 >;
			};
			counter {
				compatible = "st,stm32-counter";
				status = "disabled";
			};
		};
		timers16: timers@40014400 {
			compatible = "st,stm32-timers";
			reg = < 0x40014400 0x400 >;
			clocks = < &rcc 0xf0 0x20000 >;
			resets = < &rctl 0x1311 >;
			interrupts = < 0x75 0x0 >;
			interrupt-names = "global";
			st,prescaler = < 0x0 >;
			status = "disabled";
			pwm {
				compatible = "st,stm32-pwm";
				status = "disabled";
				#pwm-cells = < 0x3 >;
			};
			counter {
				compatible = "st,stm32-counter";
				status = "disabled";
			};
		};
		timers17: timers@40014800 {
			compatible = "st,stm32-timers";
			reg = < 0x40014800 0x400 >;
			clocks = < &rcc 0xf0 0x40000 >;
			resets = < &rctl 0x1312 >;
			interrupts = < 0x76 0x0 >;
			interrupt-names = "global";
			st,prescaler = < 0x0 >;
			status = "disabled";
			pwm {
				compatible = "st,stm32-pwm";
				status = "disabled";
				#pwm-cells = < 0x3 >;
			};
			counter {
				compatible = "st,stm32-counter";
				status = "disabled";
			};
		};
		lptim1: timers@40002400 {
			compatible = "st,stm32-lptim";
			clocks = < &rcc 0xe8 0x200 >;
			#address-cells = < 0x1 >;
			#size-cells = < 0x0 >;
			reg = < 0x40002400 0x400 >;
			interrupts = < 0x5d 0x1 >;
			interrupt-names = "wakeup";
			status = "disabled";
		};
		adc1: adc@40022000 {
			compatible = "st,stm32-adc";
			reg = < 0x40022000 0x400 >;
			clocks = < &rcc 0xd8 0x20 >;
			interrupts = < 0x12 0x0 >;
			status = "disabled";
			#io-channel-cells = < 0x1 >;
			resolutions = < 0x80e20c 0x75e20c 0x66e20c 0x53e20c 0x47e20c >;
			sampling-times = < 0x2 0x3 0x9 0x11 0x21 0x41 0x184 0x32b >;
		};
		adc2: adc@40022100 {
			compatible = "st,stm32-adc";
			reg = < 0x40022100 0x400 >;
			clocks = < &rcc 0xd8 0x20 >;
			interrupts = < 0x12 0x0 >;
			status = "disabled";
			#io-channel-cells = < 0x1 >;
			resolutions = < 0x80e20c 0x75e20c 0x66e20c 0x53e20c 0x47e20c >;
			sampling-times = < 0x2 0x3 0x9 0x11 0x21 0x41 0x184 0x32b >;
			vbat-channel = < 0xe >;
			temp-channel = < 0x12 >;
			vref-channel = < 0x13 >;
			phandle = < 0x6b >;
		};
		adc1_2: adc@40022300 {
			compatible = "st,stm32-adc";
			reg = < 0x40022300 0x400 >;
			clocks = < &rcc 0xd8 0x20 >;
			interrupts = < 0x12 0x0 >;
			status = "disabled";
			#io-channel-cells = < 0x1 >;
			resolutions = < 0x80e20c 0x75e20c 0x66e20c 0x53e20c 0x47e20c >;
			sampling-times = < 0x2 0x3 0x9 0x11 0x21 0x41 0x184 0x32b >;
		};
		dac1: dac@40007400 {
			compatible = "st,stm32-dac";
			reg = < 0x40007400 0x400 >;
			clocks = < &rcc 0xe8 0x20000000 >;
			status = "disabled";
			#io-channel-cells = < 0x1 >;
		};
		dma1: dma@40020000 {
			compatible = "st,stm32-dma-v1";
			#dma-cells = < 0x4 >;
			reg = < 0x40020000 0x400 >;
			interrupts = < 0xb 0x0 >, < 0xc 0x0 >, < 0xd 0x0 >, < 0xe 0x0 >, < 0xf 0x0 >, < 0x10 0x0 >, < 0x11 0x0 >, < 0x2f 0x0 >;
			clocks = < &rcc 0xd8 0x1 >;
			st,mem2mem;
			dma-offset = < 0x0 >;
			dma-requests = < 0x8 >;
			status = "disabled";
		};
		dma2: dma@40020400 {
			compatible = "st,stm32-dma-v1";
			#dma-cells = < 0x4 >;
			reg = < 0x40020400 0x400 >;
			interrupts = < 0x38 0x0 >, < 0x39 0x0 >, < 0x3a 0x0 >, < 0x3b 0x0 >, < 0x3c 0x0 >, < 0x44 0x0 >, < 0x45 0x0 >, < 0x46 0x0 >;
			clocks = < &rcc 0xd8 0x2 >;
			st,mem2mem;
			dma-offset = < 0x8 >;
			dma-requests = < 0x8 >;
			status = "disabled";
		};
		bdma1: bdma@58025400 {
			compatible = "st,stm32-bdma";
			#dma-cells = < 0x4 >;
			reg = < 0x58025400 0x400 >;
			interrupts = < 0x81 0x0 >, < 0x82 0x0 >, < 0x83 0x0 >, < 0x84 0x0 >, < 0x85 0x0 >, < 0x86 0x0 >, < 0x87 0x0 >, < 0x88 0x0 >;
			clocks = < &rcc 0xe0 0x200000 >;
			st,mem2mem;
			dma-offset = < 0x0 >;
			dma-requests = < 0x8 >;
			status = "disabled";
		};
		dmamux1: dmamux@40020800 {
			compatible = "st,stm32-dmamux";
			#dma-cells = < 0x3 >;
			reg = < 0x40020800 0x400 >;
			interrupts = < 0x66 0x0 >;
			clocks = < &rcc 0xd8 0x1 >;
			dma-channels = < 0x10 >;
			dma-generators = < 0x8 >;
			status = "disabled";
			dma-requests = < 0x6b >;
		};
		dmamux2: dmamux@58025800 {
			compatible = "st,stm32-dmamux";
			#dma-cells = < 0x3 >;
			reg = < 0x58025800 0x400 >;
			interrupts = < 0x80 0x0 >;
			clocks = < &rcc 0xe0 0x200000 >;
			dma-channels = < 0x8 >;
			dma-generators = < 0x8 >;
			status = "disabled";
			dma-requests = < 0x6b >;
		};
		rng: rng@48021800 {
			compatible = "st,stm32-rng";
			reg = < 0x48021800 0x400 >;
			clocks = < &rcc 0xdc 0x40 >;
			interrupts = < 0x50 0x0 >;
			status = "disabled";
			nist-config = < 0xf00d00 >;
			health-test-magic = < 0x17590abc >;
			health-test-config = < 0x72ac >;
		};
		sdmmc1: sdmmc@52007000 {
			compatible = "st,stm32-sdmmc";
			reg = < 0x52007000 0x400 >;
			clocks = < &rcc 0xd4 0x10000 >, < &rcc 0x2 0x304c >;
			resets = < &rctl 0xf90 >;
			interrupts = < 0x31 0x0 >;
			status = "disabled";
			pinctrl-0 = < &sdmmc1_d0_pc8 &sdmmc1_d1_pc9 &sdmmc1_d2_pc10 &sdmmc1_d3_pc11 &sdmmc1_ck_pc12 &sdmmc1_cmd_pd2 >;
			pinctrl-names = "default";
			cd-gpios = < &gpioi 0x8 0x11 >;
		};
		sdmmc2: sdmmc@48022400 {
			compatible = "st,stm32-sdmmc";
			reg = < 0x48022400 0x400 >;
			clocks = < &rcc 0xdc 0x200 >, < &rcc 0x2 0x304c >;
			resets = < &rctl 0x1089 >;
			interrupts = < 0x7c 0x0 >;
			status = "disabled";
		};
		mac: ethernet@40028000 {
			compatible = "st,stm32-ethernet";
			reg = < 0x40028000 0x8000 >;
			interrupts = < 0x3d 0x0 >;
			clock-names = "stmmaceth", "mac-clk-tx", "mac-clk-rx";
			clocks = < &rcc 0xd8 0x8000 >, < &rcc 0xd8 0x10000 >, < &rcc 0xd8 0x20000 >;
			status = "disabled";
		};
		fmc: memory-controller@52004000 {
			compatible = "st,stm32h7-fmc";
			reg = < 0x52004000 0x400 >;
			clocks = < &rcc 0xd4 0x1000 >;
			status = "disabled";
			pinctrl-0 = < &fmc_nbl0_pe0 &fmc_nbl1_pe1 &fmc_sdclk_pg8 &fmc_sdnwe_ph5 &fmc_sdcke1_ph7 &fmc_sdne1_ph6 &fmc_sdnras_pf11 &fmc_sdncas_pg15 &fmc_a0_pf0 &fmc_a1_pf1 &fmc_a2_pf2 &fmc_a3_pf3 &fmc_a4_pf4 &fmc_a5_pf5 &fmc_a6_pf12 &fmc_a7_pf13 &fmc_a8_pf14 &fmc_a9_pf15 &fmc_a10_pg0 &fmc_a11_pg1 &fmc_a14_pg4 &fmc_a15_pg5 &fmc_d0_pd14 &fmc_d1_pd15 &fmc_d2_pd0 &fmc_d3_pd1 &fmc_d4_pe7 &fmc_d5_pe8 &fmc_d6_pe9 &fmc_d7_pe10 &fmc_d8_pe11 &fmc_d9_pe12 &fmc_d10_pe13 &fmc_d11_pe14 &fmc_d12_pe15 &fmc_d13_pd8 &fmc_d14_pd9 &fmc_d15_pd10 >;
			pinctrl-names = "default";
			sdram: sdram {
				compatible = "st,stm32-fmc-sdram";
				#address-cells = < 0x1 >;
				#size-cells = < 0x0 >;
				status = "okay";
				power-up-delay = < 0x64 >;
				num-auto-refresh = < 0x8 >;
				mode-register = < 0x220 >;
				refresh-rate = < 0x603 >;
				bank@1 {
					reg = < 0x1 >;
					st,sdram-control = < 0x1 0x4 0x10 0x40 0x100 0xc00 0x1000 0x4000 >;
					st,sdram-timing = < 0x2 0x7 0x4 0x7 0x2 0x2 0x2 >;
				};
			};
		};
		backup_sram: memory@38800000 {
			compatible = "zephyr,memory-region", "st,stm32-backup-sram";
			reg = < 0x38800000 0x1000 >;
			clocks = < &rcc 0xe0 0x10000000 >;
			zephyr,memory-region = "BACKUP_SRAM";
			status = "disabled";
		};
		quadspi: quadspi@52005000 {
			compatible = "st,stm32-qspi";
			#address-cells = < 0x1 >;
			#size-cells = < 0x0 >;
			reg = < 0x52005000 0x34 >;
			interrupts = < 0x5c 0x0 >;
			clocks = < &rcc 0xd4 0x4000 >;
			status = "disabled";
		};
		usbotg_hs: usb@40040000 {
			compatible = "st,stm32-otghs";
			reg = < 0x40040000 0x40000 >;
			interrupts = < 0x4d 0x0 >, < 0x4a 0x0 >, < 0x4b 0x0 >;
			interrupt-names = "otghs", "ep1_out", "ep1_in";
			num-bidir-endpoints = < 0x9 >;
			ram-size = < 0x1000 >;
			maximum-speed = "full-speed";
			clocks = < &rcc 0xd8 0x2000000 >, < &rcc 0xd 0x37454 >;
			phys = < &otghs_fs_phy >;
			status = "disabled";
		};
		ltdc: display-controller@50001000 {
			compatible = "st,stm32-ltdc";
			reg = < 0x50001000 0x200 >;
			interrupts = < 0x58 0x0 >, < 0x59 0x0 >;
			interrupt-names = "ltdc", "ltdc_er";
			clocks = < &rcc 0xe4 0x8 >;
			status = "disabled";
			pinctrl-0 = < &ltdc_r0_pi15 &ltdc_r1_pj0 &ltdc_r2_pj1 &ltdc_r3_pj2 &ltdc_r4_pj3 &ltdc_r5_pj4 &ltdc_r6_pj5 &ltdc_r7_pj6 &ltdc_g0_pj7 &ltdc_g1_pj8 &ltdc_g2_pj9 &ltdc_g3_pj10 &ltdc_g4_pj11 &ltdc_g5_pk0 &ltdc_g6_pk1 &ltdc_g7_pk2 &ltdc_b0_pj12 &ltdc_b1_pj13 &ltdc_b2_pj14 &ltdc_b3_pj15 &ltdc_b4_pk3 &ltdc_b5_pk4 &ltdc_b6_pk5 &ltdc_b7_pk6 &ltdc_de_pk7 &ltdc_clk_pi14 &ltdc_hsync_pi12 &ltdc_vsync_pi13 >;
			pinctrl-names = "default";
			disp-on-gpios = < &gpioa 0x2 0x0 >;
			bl-ctrl-gpios = < &gpioa 0x1 0x0 >;
			ext-sdram = < &sdram2 >;
			width = < 0x1e0 >;
			height = < 0x110 >;
			pixel-format = < 0x10 >;
			def-back-color-red = < 0xff >;
			def-back-color-green = < 0xff >;
			def-back-color-blue = < 0xff >;
			display-timings {
				compatible = "zephyr,panel-timing";
				de-active = < 0x0 >;
				pixelclk-active = < 0x0 >;
				hsync-active = < 0x0 >;
				vsync-active = < 0x0 >;
				hsync-len = < 0x1 >;
				vsync-len = < 0xa >;
				hback-porch = < 0x2b >;
				vback-porch = < 0xc >;
				hfront-porch = < 0x8 >;
				vfront-porch = < 0x4 >;
			};
		};
		octospi1: octospi@52005000 {
			compatible = "st,stm32-ospi";
			reg = < 0x52005000 0x1000 >;
			interrupts = < 0x5c 0x0 >;
			clock-names = "ospix", "ospi-ker";
			clocks = < &rcc 0xd4 0x4000 >, < &rcc 0x2 0x1644c >;
			#address-cells = < 0x1 >;
			#size-cells = < 0x0 >;
			status = "okay";
			pinctrl-0 = < &octospim_p1_clk_pf10 &octospim_p1_ncs_pb6 &octospim_p2_io0_pi9 &octospim_p2_io1_pi10 &octospim_p1_io2_pe2 &octospim_p1_io3_pa1_c &octospim_p1_io4_pc1 &octospim_p1_io5_ph3 &octospim_p1_io6_pg9 &octospim_p1_io7_pd7 &octospim_p1_dqs_pc5 >;
			pinctrl-names = "default";
			mx25lm51245: ospi-nor-flash@0 {
				compatible = "st,stm32-ospi-nor";
				reg = < 0x0 >;
				ospi-max-frequency = < 0x2faf080 >;
				size = < 0x20000000 >;
				spi-bus-width = < 0x8 >;
				data-rate = < 0x2 >;
				status = "okay";
				sfdp-bfp = [ 53 46 44 50 06 01 02 FF 00 06 01 10 30 00 00 FF C2 00 01 04 10 01 00 FF 84 00 01 02 C0 00 00 FF 00 00 00 00 ];
				partitions {
					compatible = "fixed-partitions";
					#address-cells = < 0x1 >;
					#size-cells = < 0x1 >;
					partition@0 {
						label = "nor";
						reg = < 0x0 0x400000 >;
					};
				};
			};
		};
		octospi2: octospi@5200a000 {
			compatible = "st,stm32-ospi";
			reg = < 0x5200a000 0x1000 >;
			interrupts = < 0x96 0x0 >;
			clock-names = "ospix", "ospi-ker";
			clocks = < &rcc 0xd4 0x80000 >, < &rcc 0x2 0x1644c >;
			#address-cells = < 0x1 >;
			#size-cells = < 0x0 >;
			status = "disabled";
		};
		cryp: cryp@48021000 {
			compatible = "st,stm32-cryp";
			reg = < 0x48021000 0x400 >;
			clocks = < &rcc 0xdc 0x10 >;
			interrupts = < 0x4f 0x0 >;
			interrupt-names = "cryp";
			status = "disabled";
		};
	};
	cpus {
		#address-cells = < 0x1 >;
		#size-cells = < 0x0 >;
		cpu0: cpu@0 {
			device_type = "cpu";
			compatible = "arm,cortex-m7";
			reg = < 0x0 >;
			#address-cells = < 0x1 >;
			#size-cells = < 0x1 >;
			mpu: mpu@e000ed90 {
				compatible = "arm,armv7m-mpu";
				reg = < 0xe000ed90 0x40 >;
				arm,num-mpu-regions = < 0x10 >;
			};
		};
	};
	quadspi_memory: memory@90000000 {
		compatible = "zephyr,memory-region", "mmio-sram";
		reg = < 0x90000000 0x10000000 >;
		zephyr,memory-region = "QSPI";
		zephyr,memory-attr = "EXTMEM";
	};
	clocks {
		#address-cells = < 0x1 >;
		#size-cells = < 0x0 >;
		clk_hse: clk-hse {
			#clock-cells = < 0x0 >;
			compatible = "st,stm32-hse-clock";
			status = "okay";
			clock-frequency = < 0x16e3600 >;
			phandle = < 0x6a >;
		};
		clk_hsi: clk-hsi {
			#clock-cells = < 0x0 >;
			compatible = "st,stm32h7-hsi-clock";
			clock-frequency = < 0x3d09000 >;
			status = "disabled";
		};
		clk_hsi48: clk-hsi48 {
			#clock-cells = < 0x0 >;
			compatible = "fixed-clock";
			clock-frequency = < 0x2dc6c00 >;
			status = "okay";
		};
		clk_csi: clk-csi {
			#clock-cells = < 0x0 >;
			compatible = "fixed-clock";
			clock-frequency = < 0x3d0900 >;
			status = "disabled";
		};
		clk_lse: clk-lse {
			#clock-cells = < 0x0 >;
			compatible = "st,stm32-lse-clock";
			clock-frequency = < 0x8000 >;
			driving-capability = < 0x0 >;
			status = "disabled";
		};
		clk_lsi: clk-lsi {
			#clock-cells = < 0x0 >;
			compatible = "fixed-clock";
			clock-frequency = < 0x7d00 >;
			status = "disabled";
		};
		pll: pll@0 {
			#clock-cells = < 0x0 >;
			compatible = "st,stm32h7-pll-clock";
			reg = < 0x0 >;
			status = "okay";
			div-m = < 0xc >;
			mul-n = < 0x118 >;
			div-p = < 0x2 >;
			div-q = < 0x7 >;
			div-r = < 0x2 >;
			clocks = < &clk_hse >;
			phandle = < 0x3 >;
		};
		pll2: pll@1 {
			#clock-cells = < 0x0 >;
			compatible = "st,stm32h7-pll-clock";
			reg = < 0x1 >;
			status = "disabled";
		};
		pll3: pll@2 {
			#clock-cells = < 0x0 >;
			compatible = "st,stm32h7-pll-clock";
			reg = < 0x2 >;
			status = "okay";
			div-m = < 0x8 >;
			mul-n = < 0x3c >;
			div-p = < 0x2 >;
			div-q = < 0x2 >;
			div-r = < 0x14 >;
			clocks = < &clk_hse >;
		};
		perck: perck {
			#clock-cells = < 0x0 >;
			compatible = "st,stm32-clock-mux";
			status = "disabled";
		};
	};
	die_temp: dietemp {
		compatible = "st,stm32-temp-cal";
		ts-cal1-addr = < 0x8fff814 >;
		ts-cal2-addr = < 0x8fff818 >;
		ts-cal1-temp = < 0x1e >;
		ts-cal2-temp = < 0x82 >;
		ts-cal-vrefanalog = < 0xce4 >;
		ts-cal-resolution = < 0x10 >;
		io-channels = < &adc2 0x12 >;
		status = "disabled";
	};
	vbat: vbat {
		compatible = "st,stm32-vbat";
		ratio = < 0x4 >;
		status = "disabled";
		io-channels = < &adc2 0xe >;
	};
	vref: vref {
		compatible = "st,stm32-vref";
		vrefint-cal-addr = < 0x8fff810 >;
		vrefint-cal-mv = < 0xce4 >;
		status = "disabled";
		io-channels = < &adc2 0x13 >;
	};
	sram0: memory@24000000 {
		compatible = "zephyr,memory-region", "mmio-sram";
		reg = < 0x24000000 0x100000 >;
		zephyr,memory-region = "SRAM0";
		zephyr,memory-attr = "RAM_NOCACHE";
	};
	sram3: memory@30000000 {
		compatible = "zephyr,memory-region", "mmio-sram";
		reg = < 0x30000000 0x10000 >;
		zephyr,memory-region = "SRAM3";
	};
	sram4: memory@30010000 {
		compatible = "zephyr,memory-region", "mmio-sram";
		reg = < 0x30010000 0x10000 >;
		zephyr,memory-region = "SRAM4";
	};
	sram5: memory@38000000 {
		compatible = "zephyr,memory-region", "mmio-sram";
		reg = < 0x38000000 0x8000 >;
		zephyr,memory-region = "SRAM5";
	};
	dtcm: memory@20000000 {
		compatible = "zephyr,memory-region", "arm,dtcm";
		reg = < 0x20000000 0x20000 >;
		zephyr,memory-region = "DTCM";
	};
	itcm: memory@0 {
		compatible = "zephyr,memory-region", "arm,itcm";
		reg = < 0x0 0x10000 >;
		zephyr,memory-region = "ITCM";
	};
	otghs_fs_phy: otghs_fs_phy {
		compatible = "usb-nop-xceiv";
		#phy-cells = < 0x0 >;
		phandle = < 0x40 >;
	};
	arduino_header: connector {
		compatible = "arduino-header-r3";
		#gpio-cells = < 0x2 >;
		gpio-map-mask = < 0xffffffff 0xffffffc0 >;
		gpio-map-pass-thru = < 0x0 0x3f >;
		gpio-map = < 0x0 0x0 &gpioa 0x4 0x0 >, < 0x1 0x0 &gpioc 0x4 0x0 >, < 0x2 0x0 &gpioa 0x0 0x0 >, < 0x3 0x0 &gpioa 0x1 0x0 >, < 0x4 0x0 &gpioc 0x2 0x0 >, < 0x5 0x0 &gpioc 0x3 0x0 >, < 0x6 0x0 &gpioh 0xe 0x0 >, < 0x7 0x0 &gpioh 0xd 0x0 >, < 0x8 0x0 &gpioi 0x9 0x0 >, < 0x9 0x0 &gpioh 0x9 0x0 >, < 0xa 0x0 &gpioe 0x2 0x0 >, < 0xb 0x0 &gpioh 0xb 0x0 >, < 0xc 0x0 &gpioh 0xa 0x0 >, < 0xd 0x0 &gpioi 0xa 0x0 >, < 0xe 0x0 &gpiof 0xa 0x0 >, < 0xf 0x0 &gpioi 0x7 0x0 >, < 0x10 0x0 &gpioi 0x0 0x0 >, < 0x11 0x0 &gpiob 0xf 0x0 >, < 0x12 0x0 &gpiob 0xe 0x0 >, < 0x13 0x0 &gpioa 0xc 0x0 >, < 0x14 0x0 &gpiod 0xd 0x0 >, < 0x15 0x0 &gpiod 0xc 0x0 >;
	};
	leds {
		compatible = "gpio-leds";
		red_led: led_0 {
			gpios = < &gpiog 0xb 0x0 >;
			label = "User LD1";
		};
		blue_led: led_1 {
			gpios = < &gpiog 0x2 0x0 >;
			label = "User LD2";
		};
	};
	gpio_keys {
		compatible = "gpio-keys";
		user_button: button {
			label = "User PB";
			gpios = < &gpioc 0xd 0x0 >;
			zephyr,code = < 0xb >;
		};
	};
	lvgl_pointer {
		compatible = "zephyr,lvgl-pointer-input";
		input = < &ft5336 >;
	};
	sdram2: sdram@d0000000 {
		compatible = "zephyr,memory-region", "mmio-sram";
		device_type = "memory";
		reg = < 0xd0000000 0x1000000 >;
		zephyr,memory-region = "SDRAM2";
		zephyr,memory-attr = "RAM";
		phandle = < 0x5e >;
	};
	transceiver0: can-phy0 {
		compatible = "microchip,mcp2562fd", "can-transceiver-gpio";
		standby-gpios = < &gpioh 0x8 0x0 >;
		max-bitrate = < 0x4c4b40 >;
		#phy-cells = < 0x0 >;
		phandle = < 0x12 >;
	};
};
